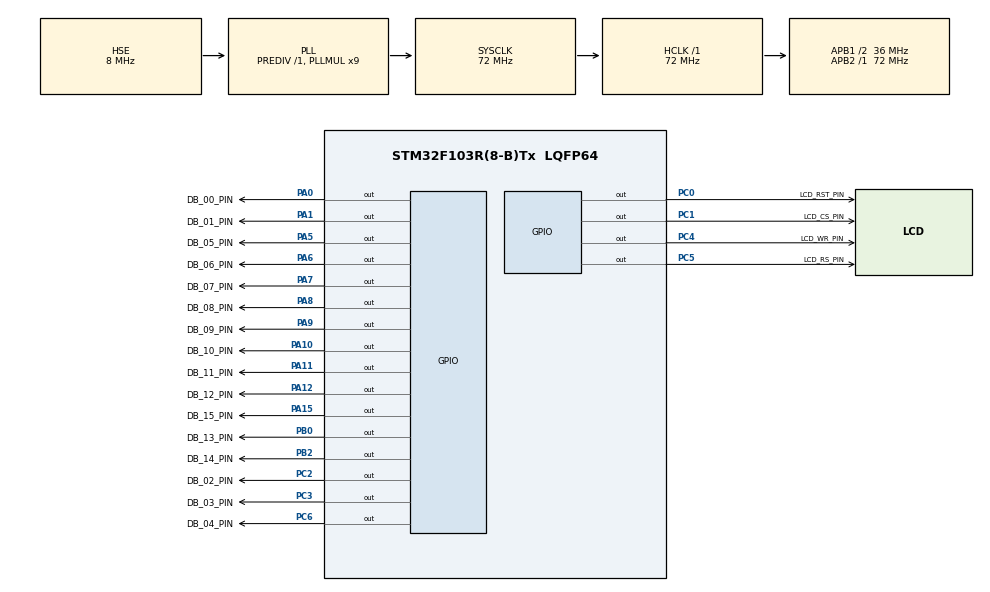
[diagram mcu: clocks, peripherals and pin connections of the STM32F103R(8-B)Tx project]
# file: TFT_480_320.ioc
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Mcu.Family=STM32F1
Mcu.Name=STM32F103R(8-B)Tx
Mcu.Package=LQFP64
NVIC.PriorityGroup=NVIC_PRIORITYGROUP_4
PA0-WKUP.GPIO_Label=D\u0412_00_PIN
PA0-WKUP.Signal=GPIO_Output
PA1.GPIO_Label=DB_01_PIN
PA1.Signal=GPIO_Output
PA10.GPIO_Label=DB_10_PIN
PA10.Signal=GPIO_Output
PA11.GPIO_Label=DB_11_PIN
PA11.Signal=GPIO_Output
PA12.GPIO_Label=DB_12_PIN
PA12.Signal=GPIO_Output
PA13.Mode=Serial_Wire
PA13.Signal=SYS_JTMS-SWDIO
PA14.Mode=Serial_Wire
PA14.Signal=SYS_JTCK-SWCLK
PA15.GPIO_Label=DB_15_PIN
PA15.Signal=GPIO_Output
PA5.GPIO_Label=DB_05_PIN
PA5.Signal=GPIO_Output
PA6.GPIO_Label=DB_06_PIN
PA6.Signal=GPIO_Output
PA7.GPIO_Label=DB_07_PIN
PA7.Signal=GPIO_Output
PA8.GPIO_Label=DB_08_PIN
PA8.Signal=GPIO_Output
PA9.GPIO_Label=DB_09_PIN
PA9.Signal=GPIO_Output
PB0.GPIO_Label=DB_13_PIN
PB0.Signal=GPIO_Output
PB2.GPIO_Label=DB_14_PIN
PB2.Signal=GPIO_Output
PC0.GPIO_Label=LCD_RST_PIN
PC0.Signal=GPIO_Output
PC1.GPIO_Label=LCD_CS_PIN
PC1.Signal=GPIO_Output
PC2.GPIO_Label=DB_02_PIN
PC2.Signal=GPIO_Output
PC3.GPIO_Label=DB_03_PIN
PC3.Signal=GPIO_Output
PC4.GPIO_Label=LCD_WR_PIN
PC4.Signal=GPIO_Output
PC5.GPIO_Label=LCD_RS_PIN
PC5.Signal=GPIO_Output
PC6.GPIO_Label=DB_04_PIN
PC6.Signal=GPIO_Output
PD0-OSC_IN.Mode=HSE-External-Oscillator
PD0-OSC_IN.Signal=RCC_OSC_IN
PD1-OSC_OUT.Mode=HSE-External-Oscillator
PD1-OSC_OUT.Signal=RCC_OSC_OUT
ProjectManager.HeapSize=0x200
ProjectManager.StackSize=0x400
ProjectManager.TargetToolchain=MDK-ARM V5
RCC.AHBFreq_Value=72000000
RCC.APB1CLKDivider=RCC_HCLK_DIV2
RCC.APB1Freq_Value=36000000
RCC.APB1TimFreq_Value=72000000
RCC.APB2Freq_Value=72000000
RCC.APB2TimFreq_Value=72000000
RCC.HCLKFreq_Value=72000000
RCC.PLLMUL=RCC_PLL_MUL9
RCC.PLLSourceVirtual=RCC_PLLSOURCE_HSE
RCC.SYSCLKFreq_VALUE=72000000
RCC.SYSCLKSource=RCC_SYSCLKSOURCE_PLLCLK
RCC.USBFreq_Value=72000000
board=custom

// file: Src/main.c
/* USER CODE BEGIN Header */
/**
  ******************************************************************************
  * @file           : main.c
  * @brief          : Main program body
  ******************************************************************************
  * @attention
  *
  * <h2><center>&copy; Copyright (c) 2019 STMicroelectronics.
  * All rights reserved.</center></h2>
  *
  * This software component is licensed by ST under BSD 3-Clause license,
  * the "License"; You may not use this file except in compliance with the
  * License. You may obtain a copy of the License at:
  *                        opensource.org/licenses/BSD-3-Clause
  *
  ******************************************************************************
  */
/* USER CODE END Header */

#include "main.h"
#include "stm32f1xx_hal.h"
#include "stm32f1xx_hal_gpio.h"
#include "stm32f1xx_hal_rcc.h"
#include <stdint.h>
#include <stdlib.h>
#include <string.h>
#include "hx8357.h"

#include "fonts/Font_24_Grotesk_Bold.h"

void SystemClock_Config(void);
static void MX_GPIO_Init(void);

int main(void)
{

  /* MCU Configuration--------------------------------------------------------*/

  /* Reset of all peripherals, Initializes the Flash interface and the Systick. */
  HAL_Init();

  /* Configure the system clock */
  SystemClock_Config();

  /* Initialize all configured peripherals */
  MX_GPIO_Init();
  /* USER CODE BEGIN 2 */
        HAL_Delay (200);
				LCD_Init();
				HAL_Delay (200);
				LCD_Rect_Fill(0, 0, 320, 480, GREEN);
				HAL_Delay (200);

				LCD_Font(45, 170, "test", _24_Grotesk_Bold, 1, RED);

  /* USER CODE END 2 */

  /* Infinite loop */
  while (1)
  {

  }
}

void SystemClock_Config(void)
{
  RCC_OscInitTypeDef RCC_OscInitStruct = {0};
  RCC_ClkInitTypeDef RCC_ClkInitStruct = {0};

  /** Initializes the CPU, AHB and APB busses clocks
  */
  RCC_OscInitStruct.OscillatorType = RCC_OSCILLATORTYPE_HSE;
  RCC_OscInitStruct.HSEState = RCC_HSE_ON;
  RCC_OscInitStruct.HSEPredivValue = RCC_HSE_PREDIV_DIV1;
  RCC_OscInitStruct.HSIState = RCC_HSI_ON;
  RCC_OscInitStruct.PLL.PLLState = RCC_PLL_ON;
  RCC_OscInitStruct.PLL.PLLSource = RCC_PLLSOURCE_HSE;
  RCC_OscInitStruct.PLL.PLLMUL = RCC_PLL_MUL9;
  if (HAL_RCC_OscConfig(&RCC_OscInitStruct) != HAL_OK)
  {
    Error_Handler();
  }
  /** Initializes the CPU, AHB and APB busses clocks
  */
  RCC_ClkInitStruct.ClockType = RCC_CLOCKTYPE_HCLK|RCC_CLOCKTYPE_SYSCLK
                              |RCC_CLOCKTYPE_PCLK1|RCC_CLOCKTYPE_PCLK2;
  RCC_ClkInitStruct.SYSCLKSource = RCC_SYSCLKSOURCE_PLLCLK;
  RCC_ClkInitStruct.AHBCLKDivider = RCC_SYSCLK_DIV1;
  RCC_ClkInitStruct.APB1CLKDivider = RCC_HCLK_DIV2;
  RCC_ClkInitStruct.APB2CLKDivider = RCC_HCLK_DIV1;

  if (HAL_RCC_ClockConfig(&RCC_ClkInitStruct, FLASH_LATENCY_2) != HAL_OK)
  {
    Error_Handler();
  }
}

static void MX_GPIO_Init(void)
{
  GPIO_InitTypeDef GPIO_InitStruct = {0};

  /* GPIO Ports Clock Enable */
  __HAL_RCC_GPIOD_CLK_ENABLE();
  __HAL_RCC_GPIOC_CLK_ENABLE();
  __HAL_RCC_GPIOA_CLK_ENABLE();
  __HAL_RCC_GPIOB_CLK_ENABLE();

  /*Configure GPIO pin Output Level */
  HAL_GPIO_WritePin(GPIOC, LCD_RST_PIN_Pin|LCD_CS_PIN_Pin|DB_02_PIN_Pin|DB_03_PIN_Pin
                          |LCD_WR_PIN_Pin|LCD_RS_PIN_Pin|DB_04_PIN_Pin, GPIO_PIN_RESET);

  /*Configure GPIO pin Output Level */
  HAL_GPIO_WritePin(GPIOA, DB_00_PIN_Pin|DB_01_PIN_Pin|DB_05_PIN_Pin|DB_06_PIN_Pin
                          |DB_07_PIN_Pin|DB_08_PIN_Pin|DB_09_PIN_Pin|DB_10_PIN_Pin
                          |DB_11_PIN_Pin|DB_12_PIN_Pin|DB_15_PIN_Pin, GPIO_PIN_RESET);

  /*Configure GPIO pin Output Level */
  HAL_GPIO_WritePin(GPIOB, DB_13_PIN_Pin|DB_14_PIN_Pin, GPIO_PIN_RESET);

  /*Configure GPIO pins : LCD_RST_PIN_Pin LCD_CS_PIN_Pin DB_02_PIN_Pin DB_03_PIN_Pin
                           LCD_WR_PIN_Pin LCD_RS_PIN_Pin DB_04_PIN_Pin */
  GPIO_InitStruct.Pin = LCD_RST_PIN_Pin|LCD_CS_PIN_Pin|DB_02_PIN_Pin|DB_03_PIN_Pin
                          |LCD_WR_PIN_Pin|LCD_RS_PIN_Pin|DB_04_PIN_Pin;
  GPIO_InitStruct.Mode = GPIO_MODE_OUTPUT_PP;
  GPIO_InitStruct.Pull = GPIO_NOPULL;
  GPIO_InitStruct.Speed = GPIO_SPEED_FREQ_HIGH;
  HAL_GPIO_Init(GPIOC, &GPIO_InitStruct);

  /*Configure GPIO pins : D__00_PIN_Pin DB_01_PIN_Pin DB_05_PIN_Pin DB_06_PIN_Pin
                           DB_07_PIN_Pin DB_08_PIN_Pin DB_09_PIN_Pin DB_10_PIN_Pin
                           DB_11_PIN_Pin DB_12_PIN_Pin DB_15_PIN_Pin */
  GPIO_InitStruct.Pin = DB_00_PIN_Pin|DB_01_PIN_Pin|DB_05_PIN_Pin|DB_06_PIN_Pin
                          |DB_07_PIN_Pin|DB_08_PIN_Pin|DB_09_PIN_Pin|DB_10_PIN_Pin
                          |DB_11_PIN_Pin|DB_12_PIN_Pin|DB_15_PIN_Pin;
  GPIO_InitStruct.Mode = GPIO_MODE_OUTPUT_PP;
  GPIO_InitStruct.Pull = GPIO_NOPULL;
  GPIO_InitStruct.Speed = GPIO_SPEED_FREQ_HIGH;
  HAL_GPIO_Init(GPIOA, &GPIO_InitStruct);

  /*Configure GPIO pins : DB_13_PIN_Pin DB_14_PIN_Pin */
  GPIO_InitStruct.Pin = DB_13_PIN_Pin|DB_14_PIN_Pin;
  GPIO_InitStruct.Mode = GPIO_MODE_OUTPUT_PP;
  GPIO_InitStruct.Pull = GPIO_NOPULL;
  GPIO_InitStruct.Speed = GPIO_SPEED_FREQ_HIGH;
  HAL_GPIO_Init(GPIOB, &GPIO_InitStruct);

}

void Error_Handler(void)
{
}

/************************ (C) COPYRIGHT STMicroelectronics *****END OF FILE****/
